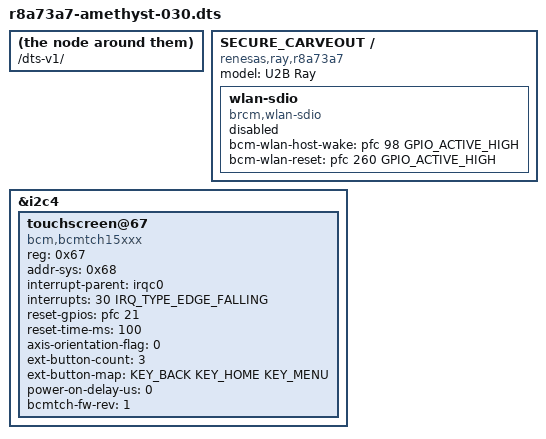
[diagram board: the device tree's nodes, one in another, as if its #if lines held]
/******************************************************************************/
/*                                                                            */
/* Copyright 2014 Broadcom Corporation                                        */
/*                                                                            */
/* Unless you and Broadcom execute a separate written software license        */
/* agreement governing use of this software, this software is licensed        */
/* to you under the terms of the GNU General Public License version 2         */
/* (the GPL), available at                                                    */
/*                                                                            */
/* http://www.broadcom.com/licenses/GPLv2.php                                 */
/*                                                                            */
/* with the following added to such license:                                  */
/*                                                                            */
/* As a special exception, the copyright holders of this software give        */
/* you permission to link this software with independent modules, and         */
/* to copy and distribute the resulting executable under terms of your        */
/* choice, provided that you also meet, for each linked independent           */
/* module, the terms and conditions of the license of that module.            */
/* An independent module is a module which is not derived from this           */
/* software. The special exception does not apply to any modifications        */
/* of the software.                                                           */
/*                                                                            */
/* Notwithstanding the above, under no circumstances may you combine          */
/* this software in any way with any other Broadcom software provided         */
/* under a license other than the GPL, without Broadcom's express             */
/* prior written consent.                                                     */
/*                                                                            */
/******************************************************************************/

/dts-v1/;
#ifdef SECURE_CARVEOUT	// Allow secure variant to insert memreserve, normally do nothing.
SECURE_CARVEOUT
#endif
#include "r8a73a7.dtsi"
#include "ray-common.dtsi"

/{
	model = "U2B Ray";
	compatible = "renesas,ray,r8a73a7", "renesas,ray", "renesas,r8a73a7";

	wlan-sdio {
		compatible = "brcm,wlan-sdio";
		bcm-wlan-host-wake = <&pfc 98 GPIO_ACTIVE_HIGH>;
		bcm-wlan-reset = <&pfc 260 GPIO_ACTIVE_HIGH>;
		status = "disabled";
	};
};

&i2c4 {
	touchscreen@67 {
		compatible = "bcm,bcmtch15xxx";
		reg = <0x67>;
		addr-sys = <0x68>;
		interrupt-parent = <&irqc0>;
		interrupts = <30 IRQ_TYPE_EDGE_FALLING>;
		reset-gpios = <&pfc 21 GPIO_ACTIVE_HIGH>;
		reset-time-ms = <100>;
		axis-orientation-flag = <0>;
		ext-button-count = <3>;
		ext-button-map = <KEY_BACK KEY_HOME KEY_MENU>;
		power-on-delay-us = <0>;
		bcmtch-fw-rev = <1>;
	};
};
